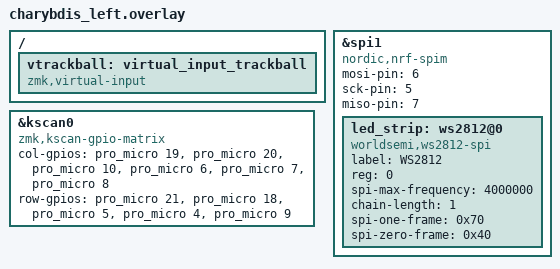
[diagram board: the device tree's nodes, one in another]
#include "charybdis.dtsi"
#include "charybdis_3610.dtsi"

&kscan0 {
	compatible = "zmk,kscan-gpio-matrix";
	
	col-gpios
		= <&pro_micro 19 (GPIO_ACTIVE_HIGH | GPIO_PULL_DOWN)>
		, <&pro_micro 20 (GPIO_ACTIVE_HIGH | GPIO_PULL_DOWN)>
		, <&pro_micro 10 (GPIO_ACTIVE_HIGH | GPIO_PULL_DOWN)>
		, <&pro_micro 6 (GPIO_ACTIVE_HIGH | GPIO_PULL_DOWN)>
		, <&pro_micro 7 (GPIO_ACTIVE_HIGH | GPIO_PULL_DOWN)>
		, <&pro_micro 8 (GPIO_ACTIVE_HIGH | GPIO_PULL_DOWN)>
		;

	row-gpios
		= <&pro_micro 21 GPIO_ACTIVE_HIGH>
		, <&pro_micro 18 GPIO_ACTIVE_HIGH>
		, <&pro_micro 5 GPIO_ACTIVE_HIGH>
		, <&pro_micro 4 GPIO_ACTIVE_HIGH>
		, <&pro_micro 9 GPIO_ACTIVE_HIGH>
		;
};

/ {
	vtrackball: virtual_input_trackball {
		compatible = "zmk,virtual-input";
	};
};

&spi1 {
	compatible = "nordic,nrf-spim";
	status = "okay";
	mosi-pin = <6>;
	// Unused pins, needed for SPI definition, but not used by the ws2812 driver itself.
	sck-pin = <5>;
	miso-pin = <7>;

	led_strip: ws2812@0 {
		compatible = "worldsemi,ws2812-spi";
		label = "WS2812";

		/* SPI */
		reg = <0>; /* ignored, but necessary for SPI bindings */
		spi-max-frequency = <4000000>;

		/* WS2812 */
		chain-length = <1>; /* arbitrary; change at will */
		spi-one-frame = <0x70>;
		spi-zero-frame = <0x40>;
	};
};

